# AT32F421xx_v2 register map
Vendor: Keil; Series: AT32F421; File version: 1.0
CPU: CM4 r0p1, little endian, no MPU, FPU, 4 interrupt priority bits
Registers are 32-bit, read-write, reset 0x0 unless marked. A register's access mark holds for its fields unless they carry their own. Offsets are from the block's base; [hi:lo] are bit positions; {n}, {i} and the like mark numbered series.

## FLASH — Flash memory controler
Base 0x40022000
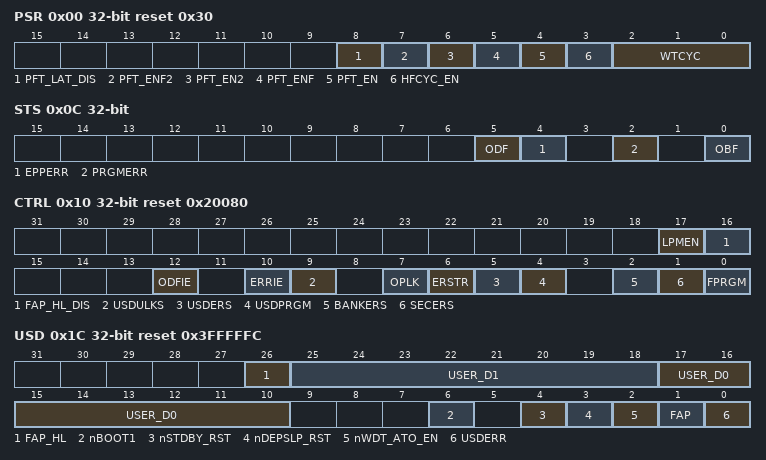
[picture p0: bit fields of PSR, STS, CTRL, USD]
0x00 PSR reset 0x30 — Performance selection register
  [8] PFT_LAT_DIS — Prefetch latency disable
  [7] PFT_ENF2 ro — Prefetch enabled flag 2
  [6] PFT_EN2 — Prefetch enable 2
  [5] PFT_ENF ro — Prefetch enabled flag
  [4] PFT_EN — Prefetch enable
  [3] HFCYC_EN — Half cycle acceleration access enable
  [2:0] WTCYC — Wait cycle
0x04 UNLOCK wo
  [31:0] UKVAL — Unlock key value
0x08 USD_UNLOCK wo
  [31:0] USD_UKVAL — User system data Unlock key value
0x0C STS — Status register
  [5] ODF — Operate done flag
  [4] EPPERR — Erase/program protection error
  [2] PRGMERR — program error
  [0] OBF ro — Operate busy flag
0x10 CTRL reset 0x20080 — Control register
  [17] LPMEN — Low power mode enable
  [16] FAP_HL_DIS — FAP high level disable
  [12] ODFIE — Operation done flag interrupt enable
  [10] ERRIE — Error interrupt enable
  [9] USDULKS — User system data unlock success
  [7] OPLK — Operation lock
  [6] ERSTR — Erasing start
  [5] USDERS — User system data erase
  [4] USDPRGM — User system data program
  [2] BANKERS — Bank erase
  [1] SECERS — Sector erase
  [0] FPRGM — Flash program
0x14 ADDR wo — Address register
  [31:0] FA — Flash Address
0x1C USD ro reset 0x3FFFFFC — User system data register
  [26] FAP_HL — FAP high level
  [25:18] USER_D1 — User data 1
  [17:10] USER_D0 — User data 0
  [6] nBOOT1 — boot1
  [4] nSTDBY_RST — Standby reset
  [3] nDEPSLP_RST — Deepsleep reset
  [2] nWDT_ATO_EN — WDT auto enable
  [1] FAP — FLASH access protection
  [0] USDERR — User system data error
0x20 EPPS ro reset 0xFFFFFFFF — Erase/program protection status register
  [31:0] EPPS — Erase/program protection status
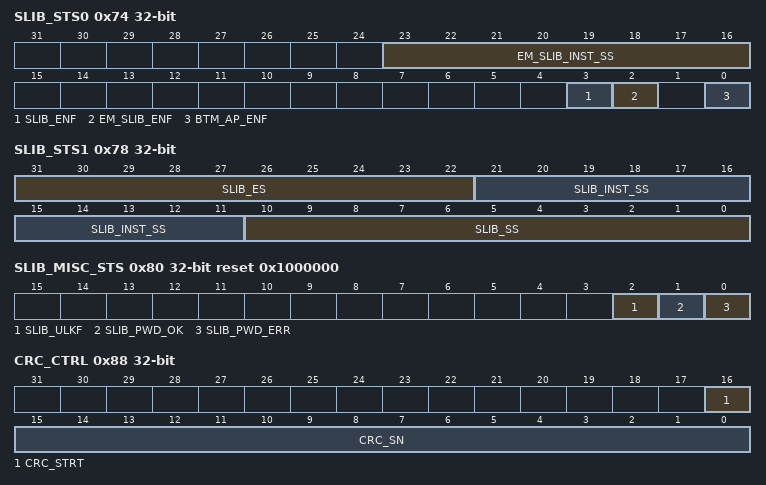
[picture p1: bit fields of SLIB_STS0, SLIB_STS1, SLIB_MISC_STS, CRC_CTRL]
0x74 SLIB_STS0 — sLib status 0 register
  [23:16] EM_SLIB_INST_SS — Extension memory sLib instruction start sector
  [3] SLIB_ENF — sLib enabled flag
  [2] EM_SLIB_ENF — Extension memory sLib enabled flag
  [0] BTM_AP_ENF — Boot memory store application code enabled flag
0x78 SLIB_STS1 — sLib status 1 register
  [31:22] SLIB_ES — sLib end sector
  [21:11] SLIB_INST_SS — sLib instruction start sector
  [10:0] SLIB_SS — sLib start sector
0x7C SLIB_PWD_CLR wo — SLIB password clear register
  [31:0] SLIB_PCLR_VAL — sLib password clear value
0x80 SLIB_MISC_STS reset 0x1000000 — sLib misc status register
  [2] SLIB_ULKF ro — sLib unlock flag
  [1] SLIB_PWD_OK ro — sLib password ok
  [0] SLIB_PWD_ERR ro — sLib password error
0x84 CRC_ADDR wo — Flash CRC data start address register
  [31:0] CRC_ADDR — CRC address
0x88 CRC_CTRL — Flash CRC controll register
  [16] CRC_STRT wo — CRC start
  [15:0] CRC_SN — CRC sector numbler
0x8C CRC_CHKR ro — FLASH CRC check result register
  [31:0] FCRC_OUT — CRC32 verification result of flash user code or SLIB code
0x160 SLIB_SET_PWD wo — sLib password setting register
  [31:0] SLIB_PSET_VAL — sLib password setting val
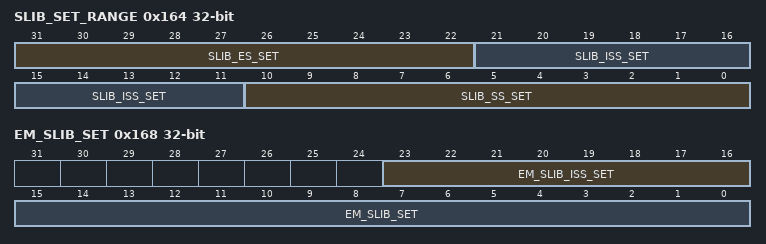
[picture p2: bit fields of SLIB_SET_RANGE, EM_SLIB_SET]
0x164 SLIB_SET_RANGE wo — Configure sLib range register
  [31:22] SLIB_ES_SET — sLib end sector setting
  [21:11] SLIB_ISS_SET — sLib instruction start sector setting
  [10:0] SLIB_SS_SET — sLib start sector setting
0x168 EM_SLIB_SET wo — Extension momery slib set register
  [23:16] EM_SLIB_ISS_SET — Extension memory sLib instruction start sector setting
  [15:0] EM_SLIB_SET — Extension memory sLib setting
0x16C BTM_MODE_SET wo — Boot memory mode setting register
  [7:0] BTM_MODE_SET — Boot memory mode setting
0x170 SLIB_UNLOCK wo
  [31:0] SLIB_UKVAL — sLib unlock key value

## NVIC — Nested Vectored Interrupt Controller
Base 0xE000E000
0x04 ICTR ro — Interrupt Controller Type Register
  [3:0] INTLINESNUM — Total number of interrupt lines in groups
0x100 ISER0 — Interrupt Set-Enable Register
  [31:0] SETENA
0x104 ISER1 — Interrupt Set-Enable Register
  [31:0] SETENA
0x180 ICER0 — Interrupt Clear-Enable Register
  [31:0] CLRENA
0x184 ICER1 — Interrupt Clear-Enable Register
  [31:0] CLRENA
0x200 ISPR0 — Interrupt Set-Pending Register
  [31:0] SETPEND
0x204 ISPR1 — Interrupt Set-Pending Register
  [31:0] SETPEND
0x280 ICPR0 — Interrupt Clear-Pending Register
  [31:0] CLRPEND
0x284 ICPR1 — Interrupt Clear-Pending Register
  [31:0] CLRPEND
0x300 IABR0 ro — Interrupt Active Bit Register
  [31:0] ACTIVE
0x304 IABR1 ro — Interrupt Active Bit Register
  [31:0] ACTIVE
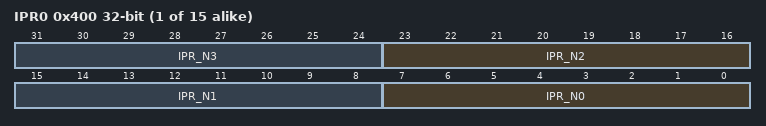
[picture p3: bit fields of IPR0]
{0x400+4i} IPR{i} (i=0..14) — Interrupt Priority Register
  [8n+7:8n] IPR_N{n} (n=0..3)
0xF00 STIR wo — Software Triggered Interrupt Register
  [8:0] INTID — interrupt to be triggered

## SCFG — System configuration controller
Base 0x40010000
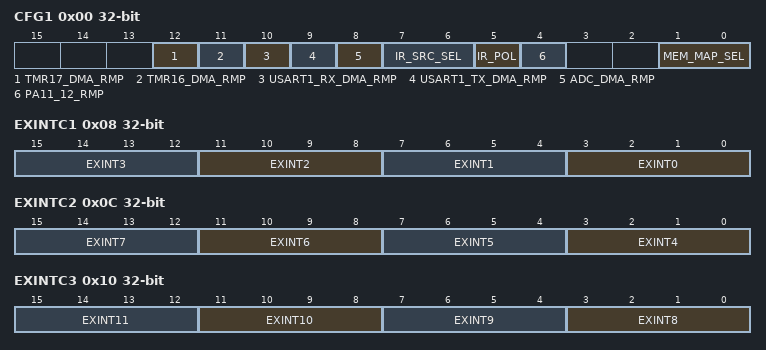
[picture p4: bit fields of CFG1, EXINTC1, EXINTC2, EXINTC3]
0x00 CFG1 — configuration register 1
  [12] TMR17_DMA_RMP — TMR17 DMA remap
  [11] TMR16_DMA_RMP — TMR16 DMA remap
  [10] USART1_RX_DMA_RMP — USART1 receive DMA remap
  [9] USART1_TX_DMA_RMP — USART1 transmit DMA remap
  [8] ADC_DMA_RMP — ADC DMA remap
  [7:6] IR_SRC_SEL — IRTMR source select
  [5] IR_POL — IRTMR Polariyt select
  [4] PA11_12_RMP — PA11 PA12 Remap
  [1:0] MEM_MAP_SEL — Memory address mapping selection bits
0x08 EXINTC1 — external interrupt configuration register 1
  [4n+3:4n] EXINT{n} (n=0..3) — EXINT {n} configuration bits
0x0C EXINTC2 — external interrupt configuration register 2
  [4n-13:4n-16] EXINT{n} (n=4..7) — EXINT {n} configuration bits
0x10 EXINTC3 — external interrupt configuration register 3
  [4n-29:4n-32] EXINT{n} (n=8..11) — EXINT {n} configuration bits
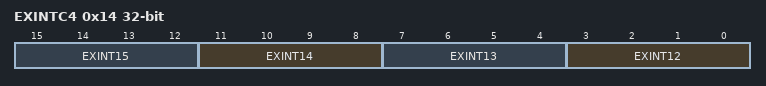
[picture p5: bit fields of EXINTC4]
0x14 EXINTC4 — external interrupt configuration register 4
  [4n-45:4n-48] EXINT{n} (n=12..15) — EXINT {n} configuration bits
